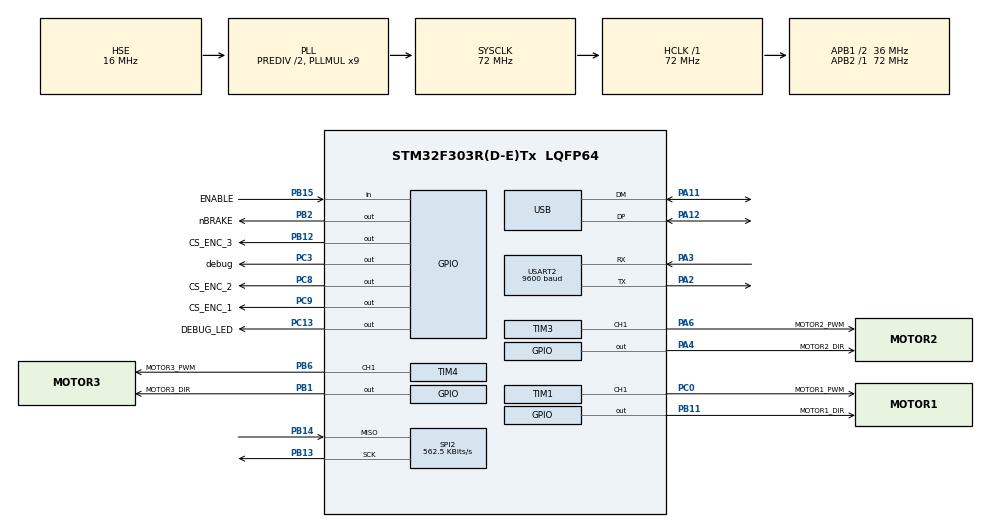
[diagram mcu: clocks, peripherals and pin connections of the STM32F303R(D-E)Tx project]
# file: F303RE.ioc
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Mcu.Family=STM32F3
Mcu.Name=STM32F303R(D-E)Tx
Mcu.Package=LQFP64
NVIC.PriorityGroup=NVIC_PRIORITYGROUP_4
NVIC.USART2_IRQn=true\:0\:0\:false\:false\:true\:true\:true\:true
NVIC.USB_LP_CAN_RX0_IRQn=true\:0\:0\:false\:false\:true\:false\:true\:true
PA11.Mode=Device
PA11.Signal=USB_DM
PA12.Mode=Device
PA12.Signal=USB_DP
PA2.Mode=Asynchronous
PA2.Signal=USART2_TX
PA3.Mode=Asynchronous
PA3.Signal=USART2_RX
PA4.GPIO_Label=MOTOR2_DIR
PA4.Signal=GPIO_Output
PA6.GPIO_Label=MOTOR2_PWM
PA6.Signal=S_TIM3_CH1
PB1.GPIO_Label=MOTOR3_DIR
PB1.Signal=GPIO_Output
PB11.GPIO_Label=MOTOR1_DIR
PB11.Signal=GPIO_Output
PB12.GPIO_Label=CS_ENC_3
PB12.Signal=GPIO_Output
PB13.Mode=RX_Only_Simplex_Unidirect_Master
PB13.Signal=SPI2_SCK
PB14.Mode=RX_Only_Simplex_Unidirect_Master
PB14.Signal=SPI2_MISO
PB15.GPIO_Label=ENABLE
PB15.Signal=GPIO_Input
PB2.GPIO_Label=nBRAKE
PB2.Signal=GPIO_Output
PB6.GPIO_Label=MOTOR3_PWM
PB6.Signal=S_TIM4_CH1
PC0.GPIO_Label=MOTOR1_PWM
PC0.Signal=S_TIM1_CH1
PC13.GPIO_Label=DEBUG_LED
PC13.Signal=GPIO_Output
PC3.GPIO_Label=debug
PC3.Signal=GPIO_Output
PC8.GPIO_Label=CS_ENC_2
PC8.Signal=GPIO_Output
PC9.GPIO_Label=CS_ENC_1
PC9.Signal=GPIO_Output
PF0-OSC_IN.Mode=HSE-External-Oscillator
PF0-OSC_IN.Signal=RCC_OSC_IN
PF1-OSC_OUT.Mode=HSE-External-Oscillator
PF1-OSC_OUT.Signal=RCC_OSC_OUT
ProjectManager.HeapSize=0x200
ProjectManager.StackSize=0x400
ProjectManager.TargetToolchain=STM32CubeIDE
RCC.AHBFreq_Value=72000000
RCC.APB1CLKDivider=RCC_HCLK_DIV2
RCC.APB1Freq_Value=36000000
RCC.APB1TimFreq_Value=72000000
RCC.APB2Freq_Value=72000000
RCC.APB2TimFreq_Value=72000000
RCC.CortexFreq_Value=72000000
RCC.HCLKFreq_Value=72000000
RCC.HSE_VALUE=16000000
RCC.HSI_VALUE=8000000
RCC.LSE_VALUE=32768
RCC.PLLDivider=RCC_PREDIV_DIV2
RCC.PLLMUL=RCC_PLL_MUL9
RCC.PRESCALERUSB=RCC_USBCLKSOURCE_PLL_DIV1_5
RCC.SYSCLKFreq_VALUE=72000000
RCC.SYSCLKSourceVirtual=RCC_SYSCLKSOURCE_PLLCLK
RCC.USBFreq_Value=48000000
SH.S_TIM1_CH1.0=TIM1_CH1,PWM Generation1 CH1
SH.S_TIM3_CH1.0=TIM3_CH1,PWM Generation1 CH1
SH.S_TIM4_CH1.0=TIM4_CH1,PWM Generation1 CH1
SPI2.BaudRatePrescaler=SPI_BAUDRATEPRESCALER_64
SPI2.CLKPolarity=SPI_POLARITY_HIGH
SPI2.CalculateBaudRate=562.5 KBits/s
SPI2.DataSize=SPI_DATASIZE_8BIT
SPI2.Direction=SPI_DIRECTION_2LINES_RXONLY
SPI2.Mode=SPI_MODE_MASTER
SPI2.VirtualType=VM_MASTER
TIM1.Channel-PWM\ Generation1\ CH1=TIM_CHANNEL_1
TIM1.Period=99
TIM1.Prescaler=71
TIM3.Channel-PWM\ Generation1\ CH1=TIM_CHANNEL_1
TIM3.Period=99
TIM3.Prescaler=71
TIM4.Channel-PWM\ Generation1\ CH1=TIM_CHANNEL_1
TIM4.Period=999
TIM4.Prescaler=71
USART2.BaudRate=9600
USART2.VirtualMode-Asynchronous=VM_ASYNC
USB_DEVICE.CLASS_NAME_FS=CDC
USB_DEVICE.VirtualMode=Cdc
USB_DEVICE.VirtualModeFS=Cdc_FS
VP_USB_DEVICE_VS_USB_DEVICE_CDC_FS.Mode=CDC_FS
board=custom

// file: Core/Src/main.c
/* USER CODE BEGIN Header */
/**
  ******************************************************************************
  * @file           : main.c
  * @brief          : Main program body
  ******************************************************************************
  * @attention
  *
  * Copyright (c) 2024 STMicroelectronics.
  * All rights reserved.
  *
  * This software is licensed under terms that can be found in the LICENSE file
  * in the root directory of this software component.
  * If no LICENSE file comes with this software, it is provided AS-IS.
  *
  ******************************************************************************
  */
/* USER CODE END Header */
#include "main.h"
#include "spi.h"
#include "tim.h"
#include "usart.h"
#include "usb_device.h"
#include "gpio.h"

void SystemClock_Config(void);

int main(void)
{

  /* MCU Configuration--------------------------------------------------------*/

  /* Reset of all peripherals, Initializes the Flash interface and the Systick. */
  HAL_Init();

  /* Configure the system clock */
  SystemClock_Config();

  /* Initialize all configured peripherals */
  MX_GPIO_Init();
  MX_TIM1_Init();
  MX_TIM3_Init();
  MX_TIM4_Init();
  MX_SPI2_Init();
  MX_USART2_UART_Init();
  MX_USB_DEVICE_Init();

  /* Infinite loop */
  while (1)
  {

    /* USER CODE BEGIN 3 */
	  if (CDC_Transmit_FS((uint8_t*)"USB Connected\n", 14) == USBD_OK) {
	      HAL_GPIO_TogglePin(DEBUG_LED_GPIO_Port, DEBUG_LED_Pin);
	  }

	  char buffer[20];
	  int random_number = rand() % 1000;
	  int length = snprintf(buffer, sizeof(buffer), "Rand: %d\n", random_number);

	  CDC_Transmit_FS((uint8_t*)buffer, length);

  }
  /* USER CODE END 3 */
}

void SystemClock_Config(void)
{
  RCC_OscInitTypeDef RCC_OscInitStruct = {0};
  RCC_ClkInitTypeDef RCC_ClkInitStruct = {0};
  RCC_PeriphCLKInitTypeDef PeriphClkInit = {0};

  /** Initializes the RCC Oscillators according to the specified parameters
  * in the RCC_OscInitTypeDef structure.
  */
  RCC_OscInitStruct.OscillatorType = RCC_OSCILLATORTYPE_HSE;
  RCC_OscInitStruct.HSEState = RCC_HSE_ON;
  RCC_OscInitStruct.HSIState = RCC_HSI_ON;
  RCC_OscInitStruct.PLL.PLLState = RCC_PLL_ON;
  RCC_OscInitStruct.PLL.PLLSource = RCC_PLLSOURCE_HSE;
  RCC_OscInitStruct.PLL.PLLMUL = RCC_PLL_MUL9;
  RCC_OscInitStruct.PLL.PREDIV = RCC_PREDIV_DIV2;
  if (HAL_RCC_OscConfig(&RCC_OscInitStruct) != HAL_OK)
  {
    Error_Handler();
  }

  /** Initializes the CPU, AHB and APB buses clocks
  */
  RCC_ClkInitStruct.ClockType = RCC_CLOCKTYPE_HCLK|RCC_CLOCKTYPE_SYSCLK
                              |RCC_CLOCKTYPE_PCLK1|RCC_CLOCKTYPE_PCLK2;
  RCC_ClkInitStruct.SYSCLKSource = RCC_SYSCLKSOURCE_PLLCLK;
  RCC_ClkInitStruct.AHBCLKDivider = RCC_SYSCLK_DIV1;
  RCC_ClkInitStruct.APB1CLKDivider = RCC_HCLK_DIV2;
  RCC_ClkInitStruct.APB2CLKDivider = RCC_HCLK_DIV1;

  if (HAL_RCC_ClockConfig(&RCC_ClkInitStruct, FLASH_LATENCY_2) != HAL_OK)
  {
    Error_Handler();
  }
  PeriphClkInit.PeriphClockSelection = RCC_PERIPHCLK_USB|RCC_PERIPHCLK_USART2
                              |RCC_PERIPHCLK_TIM1|RCC_PERIPHCLK_TIM34;
  PeriphClkInit.Usart2ClockSelection = RCC_USART2CLKSOURCE_PCLK1;
  PeriphClkInit.USBClockSelection = RCC_USBCLKSOURCE_PLL_DIV1_5;
  PeriphClkInit.Tim1ClockSelection = RCC_TIM1CLK_HCLK;
  PeriphClkInit.Tim34ClockSelection = RCC_TIM34CLK_HCLK;
  if (HAL_RCCEx_PeriphCLKConfig(&PeriphClkInit) != HAL_OK)
  {
    Error_Handler();
  }
}

void Error_Handler(void)
{
  __disable_irq();
  while (1)
  {
  }
}
